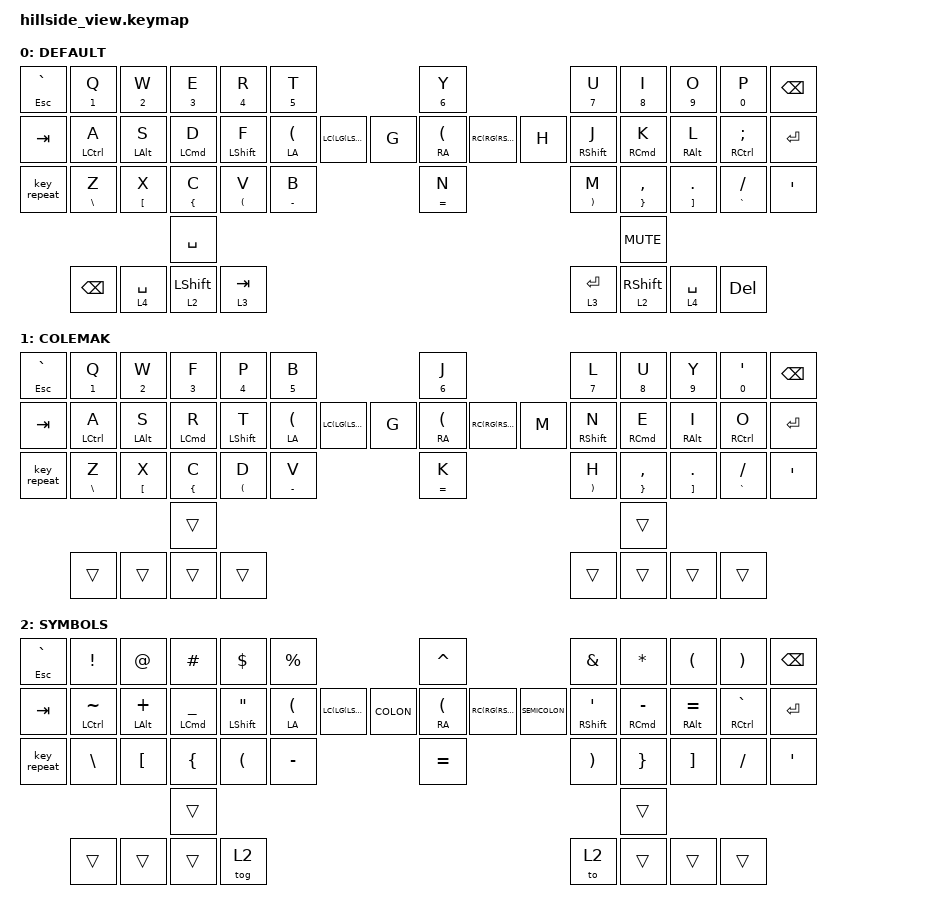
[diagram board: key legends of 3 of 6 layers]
#include <behaviors.dtsi>
#include <dt-bindings/zmk/bt.h>
#include <dt-bindings/zmk/keys.h>

// Left bottom row pinky 2nd column

#ifndef LB5

#define LB5 24

#endif

// Right bottom row pinky 2nd column
#ifndef RB5

#define RB5 35

#endif

#define DEF 0
#define CMK 1
#define SWP 2
#define SYM 3
#define NUM 4
#define NAV 5
#define ADJ 6
#define QUICK_TAP_MS 300

&sk {
    release-after-ms = <600>;
    quick-release;
};

/ {
    conditional_layers {
        compatible = "zmk,conditional-layers";

        tri_layer {
            if-layers = <2 3>;
            then-layer = <5>;
        };
    };

    combos {
        compatible = "zmk,combos";

        caps {
            timeout-ms = <50>;
            key-positions = <40 43>;
            bindings = <&caps_word>;
        };

        // symbols

        cb_esc {
            bindings = <&ht ESC GRAVE>;
            key-positions = <1 2>;
            timeout-ms = <300>;
        };

        cb_soft_off_right {
            bindings = <&soft_off>;
            key-positions = <6 11>;
            layers = <5>;
            timeout-ms = <100>;
        };

        cb_soft_off_left {
            bindings = <&soft_off>;
            key-positions = <0 5>;
            layers = <5>;
            timeout-ms = <100>;
        };

        cb_reset_right {
            bindings = <&sys_reset>;
            key-positions = <18 23>;
            layers = <5>;
            timeout-ms = <100>;
        };

        cb_reset_left {
            bindings = <&sys_reset>;
            key-positions = <12 17>;
            layers = <5>;
            timeout-ms = <100>;
        };

        cb_bootloader_right {
            bindings = <&bootloader>;
            key-positions = <30 35>;
            layers = <5>;
            timeout-ms = <100>;
        };

        cb_bootloader_left {
            bindings = <&bootloader>;
            key-positions = <24 29>;
            layers = <5>;
            timeout-ms = <100>;
        };
    };

    behaviors {
        lt_qk: layer_toggle_quick {
            compatible = "zmk,behavior-hold-tap";
            label = "LAYER_TOGGLE_QUICK";
            #binding-cells = <2>;
            flavor = "tap-preferred";
            tapping-term-ms = <300>;
            quick-tap-ms = <100>;
            bindings = <&mo>, <&kp>;
        };

        mt_sk: mod_tap_sticky {
            compatible = "zmk,behavior-hold-tap";
            label = "MOD_TAP_STICKY";
            #binding-cells = <2>;
            flavor = "tap-preferred";
            tapping-term-ms = <150>;
            quick-tap-ms = <200>;
            bindings = <&sk>, <&kp>;
        };

        ht: hold_tap {
            compatible = "zmk,behavior-hold-tap";
            label = "HOLD_TAP";
            #binding-cells = <2>;
            tapping_term_ms = <300>;
            quick_tap_ms = <300>;
            flavor = "tap-preferred";
            bindings = <&kp>, <&kp>;

            tapping-term-ms = <300>;
            quick-tap-ms = <300>;
        };

        hml: homewrow_mods_left {
            compatible = "zmk,behavior-hold-tap";
            #binding-cells = <2>;
            label = "HOMEROW_MODS_LEFT_HAND";
            bindings = <&kp>, <&kp>;

            tapping-term-ms = <300>;
            hold-trigger-key-positions = <13 14 15 42 43 44 45 30 7 8 9 10 11 19 20 21 22 23 31 32 33 34 35 6 18 16 41 40 39 38>;
            flavor = "balanced";
        };

        hmr: homewrow_mods_right {
            compatible = "zmk,behavior-hold-tap";
            #binding-cells = <2>;
            label = "HOMEROW_MODS_RIGHT_HAND";
            bindings = <&kp>, <&kp>;

            tapping-term-ms = <300>;
            hold-trigger-key-positions = <0 1 2 3 4 5 12 13 14 15 16 17 24 25 26 27 28 29 38 19 20 21 22 39 40 41 42 43 45 44>;
            flavor = "balanced";
        };

        dly_bt: dly_bt {
            compatible = "zmk,behavior-hold-tap";
            label = "DLY_BT";
            bindings = <&bt>, <&none>;

            #binding-cells = <2>;
            tapping-term-ms = <1000>;
        };

        sk_layer: sk_layer {
            compatible = "zmk,behavior-hold-tap";
            label = "SK_LAYER";
            bindings = <&mo>, <&sk>;

            #binding-cells = <2>;
            tapping-term-ms = <200>;
            hold-while-undecided;
        };
    };

    keymap {
        compatible = "zmk,keymap";

        default_layer {
            label = "DEFAULT";
            bindings = <
&ht ESCAPE GRAVE  &ht N1 Q         &ht N2 W            &ht N3 E           &ht N4 R                &ht N5 T                      &ht N6 Y                  &ht N7 U                 &ht N8 I               &ht N9 O               &ht N0 P         &kp BACKSPACE
&kp TAB           &hml LCTRL A     &hml LALT S         &hml LCMD D        &hml LSHFT F            &hml LA(LC(LG(LSHFT))) G      &hmr RA(RC(RG(RSHFT))) H  &hmr RSHFT J             &hmr RCMD K            &hmr RALT L            &hmr RCTRL SEMI  &kp ENTER
&key_repeat       &ht BACKSLASH Z  &ht LEFT_BRACKET X  &ht LEFT_BRACE C   &ht LEFT_PARENTHESIS V  &ht MINUS B                   &ht EQUAL N               &ht RIGHT_PARENTHESIS M  &ht RIGHT_BRACE COMMA  &ht RIGHT_BRACKET DOT  &ht GRAVE FSLH   &kp SQT
                                                       &kp SPACE                                                                                                                   &kp C_MUTE
                  &kp BACKSPACE    &lt_qk 4 SPACE      &sk_layer 2 LSHFT  &lt_qk 3 TAB                                                                    &lt_qk 3 ENTER           &sk_layer 2 RSHFT      &lt_qk 4 SPACE         &kp DEL
            >;

            sensor-bindings = <&inc_dec_kp PG_UP PG_DN &inc_dec_kp C_VOL_UP C_VOL_DN>;
        };

        colemak_dhrs_layer {
            label = "COLEMAK";
            bindings = <
&ht ESC GRAVE  &ht N1 Q         &ht N2 W            &ht N3 F          &ht N4 P                &ht N5 B                      &ht N6 J                  &ht N7 L                 &ht N8 U               &ht N9 Y               &ht N0 SQT      &kp BSPC
&kp TAB        &hml LCTRL A     &hml LALT S         &hml LCMD R       &hml LSHFT T            &hml LA(LC(LG(LSHFT))) G      &hmr RA(RC(RG(RSHFT))) M  &hmr RSHFT N             &hmr RCMD E            &hmr RALT I            &hmr RCTRL O    &kp ENTER
&key_repeat    &ht BACKSLASH Z  &ht LEFT_BRACKET X  &ht LEFT_BRACE C  &ht LEFT_PARENTHESIS D  &ht MINUS V                   &ht EQUAL K               &ht RIGHT_PARENTHESIS H  &ht RIGHT_BRACE COMMA  &ht RIGHT_BRACKET DOT  &ht GRAVE FSLH  &kp APOS
                                                    &trans                                                                                                                     &trans
               &trans           &trans              &trans            &trans                                                                          &trans                   &trans                 &trans                 &trans
            >;
        };

        sym_layer {
            label = "SYMBOLS";
            bindings = <
&ht ESC GRAVE  &kp EXCL          &kp AT            &kp HASH              &kp DLLR                  &kp PRCNT                         &kp CARET                         &kp AMPS               &kp ASTERISK     &kp LPAR           &kp RPAR          &kp BSPC
&kp TAB        &hml LCTRL TILDE  &hml LALT PLUS    &hml LCMD UNDERSCORE  &hml LSHFT DOUBLE_QUOTES  &hml LA(LC(LG(LSHFT))) COLON      &hmr RA(RC(RG(RSHFT))) SEMICOLON  &hmr RSHFT SQT         &hmr RCMD MINUS  &hmr RALT EQUAL    &hmr RCTRL GRAVE  &kp ENTER
&key_repeat    &kp BACKSLASH     &kp LEFT_BRACKET  &kp LEFT_BRACE        &kp LEFT_PARENTHESIS      &kp MINUS                         &kp EQUAL                         &kp RIGHT_PARENTHESIS  &kp RIGHT_BRACE  &kp RIGHT_BRACKET  &kp FSLH          &kp APOS
                                                   &trans                                                                                                                                     &trans
               &trans            &trans            &trans                &tog 2                                                                                        &to 2                  &trans           &trans             &trans
            >;

            sensor-bindings = <&inc_dec_kp UP DOWN &inc_dec_kp C_NEXT C_PREV>;
        };

        num_layer {
            label = "NUMBERS";
            bindings = <
&ht ESC GRAVE  &ht F1 N1  &ht F2 N2  &ht F3 N3     &ht F4 N4  &ht F5 N5                  &ht F6 N6   &ht F7 N7        &ht F8 N8  &ht F9 N9        &ht F10 N0                 &kp BSPC
&kp TAB        &kp LCTRL  &kp LALT   &kp LCMD      &kp LSHFT  &kp LA(LC(LG(LSHFT)))      &kp PERIOD  &ht F4 NUMBER_4  &ht F5 N5  &ht F6 NUMBER_6  &ht F11 LEFT_PARENTHESIS   &kp ENTER
&key_repeat    &kp PLUS   &kp MINUS  &kp ASTERISK  &kp SLASH  &kp EQUAL                  &kp N0      &ht F1 N1        &ht F2 N2  &ht F3 N3        &ht F12 RIGHT_PARENTHESIS  &kp APOS
                                     &trans                                                                           &trans
               &trans     &to 3      &trans        &trans                                            &trans           &trans     &to 3            &trans
            >;

            sensor-bindings = <&inc_dec_kp HOME END &inc_dec_kp C_NEXT C_PREV>;
        };

        nav_layer {
            label = "Navigation";
            bindings = <
&kp ESC      &kp LG(LEFT_BRACKET)   &kp HOME   &kp UP     &kp END    &kp PG_UP      &kp C_RW               &kp RC(F2)       &kp C_FF    &kp C_VOLUME_UP  &kp RC(F4)  &kp BSPC
&kp TAB      &kp LG(RIGHT_BRACKET)  &kp LEFT   &kp DOWN   &kp RIGHT  &kp PG_DN      &kp RA(RC(RG(RSHFT)))  &kp RSHFT        &kp RCMD    &kp RALT         &kp RCTRL   &kp ENTER
&key_repeat  &kp LG(Z)              &kp LG(X)  &kp LG(C)  &kp LG(V)  &kp LG(F)      &kp C_PREV             &ht C_STOP C_PP  &kp C_NEXT  &kp C_VOL_DN     &kp C_MUTE  &kp C_RECORD
                                               &trans                                                                       &trans
             &trans                 &trans     &trans     &trans                                           &trans           &trans      &trans           &trans
            >;

            // F15 and F14 are brightness controls for macOS

            sensor-bindings = <&inc_dec_kp F15 F14 &inc_dec_kp PG_UP PG_DN>;
        };

        Adjustment {
            label = "ADJUST";
            bindings = <
&dly_bt BT_CLR_ALL 0  &none   &none   &trans  &trans  &trans      &trans  &bt BT_PRV    &dly_bt BT_CLR  &bt BT_NXT    &none   &none
&none                 &none   &trans  &trans  &trans  &trans      &trans  &bt BT_SEL 3  &bt BT_SEL 4    &trans        &none   &none
&none                 &none   &trans  &trans  &trans  &trans      &trans  &bt BT_SEL 0  &bt BT_SEL 1    &bt BT_SEL 2  &none   &none
                                      &trans                                            &trans
                      &trans  &to 1   &trans  &trans                      &trans        &trans          &to 0         &trans
            >;

            sensor-bindings = <&inc_dec_kp F15 F14 &inc_dec_kp PG_UP PG_DN>;
        };
    };
};
